VERSION ""

NS_ :

BS_:

BU_:

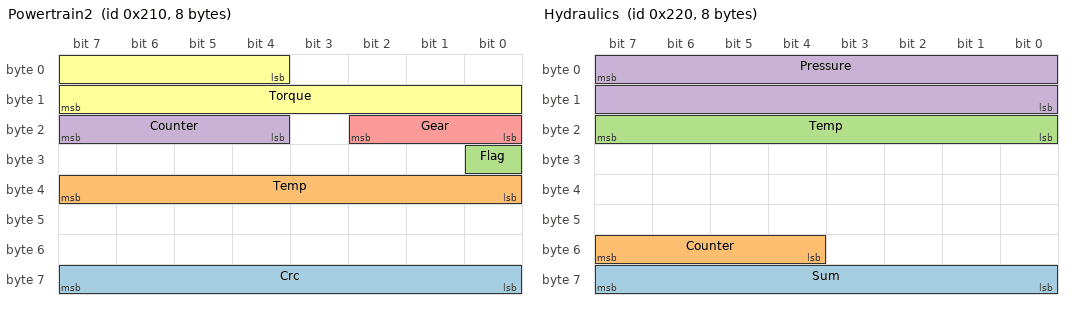
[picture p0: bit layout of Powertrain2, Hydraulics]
BO_ 528 Powertrain2: 8 Vector__XXX
 SG_ Crc : 56|8@1+ (1,0) [0|255] "" Vector__XXX
 SG_ Temp : 32|8@1+ (1,-40) [-40|215] "degC" Vector__XXX
 SG_ Flag : 24|1@1+ (1,0) [0|1] "" Vector__XXX
 SG_ Counter : 20|4@1+ (1,0) [0|15] "" Vector__XXX
 SG_ Gear : 16|3@1+ (1,0) [0|7] "" Vector__XXX
 SG_ Torque : 4|12@1+ (0.5,-500) [-500|1500] "Nm" Vector__XXX

BO_ 544 Hydraulics: 8 Vector__XXX
 SG_ Sum : 56|8@1+ (1,0) [0|255] "" Vector__XXX
 SG_ Counter : 52|4@1+ (1,0) [0|15] "" Vector__XXX
 SG_ Temp : 16|8@1+ (1,-40) [-40|215] "degC" Vector__XXX
 SG_ Pressure : 7|16@0+ (0.1,0) [0|6000] "kPa" Vector__XXX

BA_DEF_ BO_  "GenMsgCycleTime" INT 0 65535;
BA_DEF_DEF_  "GenMsgCycleTime" 0;
BA_ "GenMsgCycleTime" BO_ 528 20;
BA_ "GenMsgCycleTime" BO_ 544 20;
